AUTOSAR XML (schema 4-2-2)
package /ComponentTypes
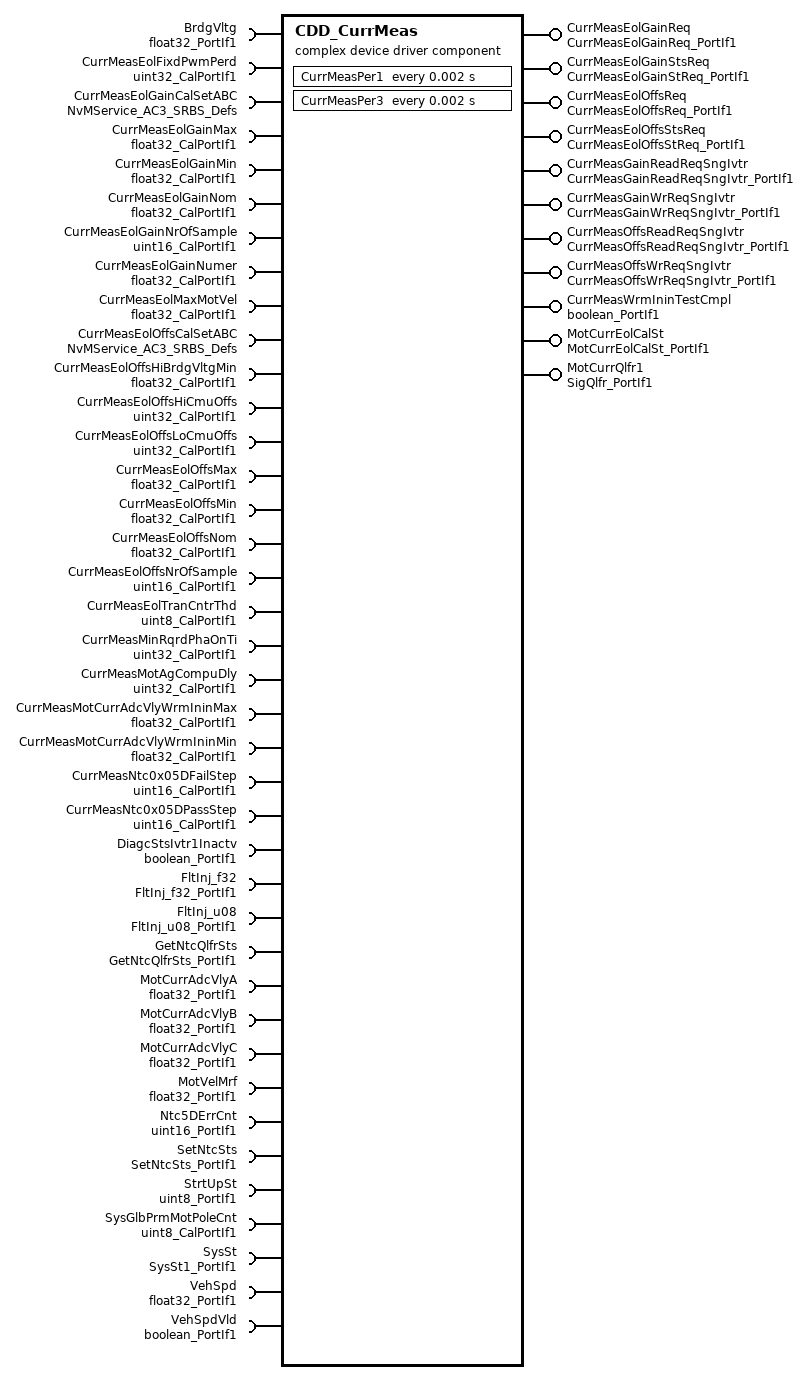
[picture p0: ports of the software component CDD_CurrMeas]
  complex device driver sw component type CDD_CurrMeas
    11 x provide port:
      CurrMeasEolGainReq: server-com-spec{operation=Oper, queue-length=1}, provided-interface=CurrMeasEolGainReq_PortIf1
      CurrMeasEolGainStsReq: server-com-spec{operation=Oper, queue-length=1}, provided-interface=CurrMeasEolGainStReq_PortIf1
      CurrMeasEolOffsReq: server-com-spec{operation=Oper, queue-length=1}, provided-interface=CurrMeasEolOffsReq_PortIf1
      CurrMeasEolOffsStsReq: server-com-spec{operation=Oper, queue-length=1}, provided-interface=CurrMeasEolOffsStReq_PortIf1
      CurrMeasGainReadReqSngIvtr: server-com-spec{operation=Oper, queue-length=1}, provided-interface=CurrMeasGainReadReqSngIvtr_PortIf1
      CurrMeasGainWrReqSngIvtr: server-com-spec{operation=Oper, queue-length=1}, provided-interface=CurrMeasGainWrReqSngIvtr_PortIf1
      CurrMeasOffsReadReqSngIvtr: server-com-spec{operation=Oper, queue-length=1}, provided-interface=CurrMeasOffsReadReqSngIvtr_PortIf1
      CurrMeasOffsWrReqSngIvtr: server-com-spec{operation=Oper, queue-length=1}, provided-interface=CurrMeasOffsWrReqSngIvtr_PortIf1
      CurrMeasWrmIninTestCmpl: nonqueued-sender-com-spec{data-element=Logl, init-value=0}, provided-interface=boolean_PortIf1
      MotCurrEolCalSt: nonqueued-sender-com-spec{data-element=Val, init-value=0}, provided-interface=MotCurrEolCalSt_PortIf1
      MotCurrQlfr1: nonqueued-sender-com-spec{data-element=Val, init-value=0}, provided-interface=SigQlfr_PortIf1
    39 x require port:
      BrdgVltg: nonqueued-receiver-com-spec{data-element=Val, filter=data-filter-type=ALWAYS, init-value=6}, required-interface=float32_PortIf1
      CurrMeasEolFixdPwmPerd: parameter-require-com-spec{init-value=62500, parameter=Val}, required-interface=uint32_CalPortIf1
      CurrMeasEolGainCalSetABC: required-com-specs=[EraseBlock, GetErrorStatus, InvalidateNvBlock, ReadBlock, RestoreBlockDefaults, SetRamBlockStatus, WriteBlock], required-interface=NvMService_AC3_SRBS_Defs
      CurrMeasEolGainMax: parameter-require-com-spec{init-value=76, parameter=Val}, required-interface=float32_CalPortIf1
      CurrMeasEolGainMin: parameter-require-com-spec{init-value=56, parameter=Val}, required-interface=float32_CalPortIf1
      CurrMeasEolGainNom: parameter-require-com-spec{init-value=66.66, parameter=Val}, required-interface=float32_CalPortIf1
      CurrMeasEolGainNrOfSample: parameter-require-com-spec{init-value=5, parameter=Val}, required-interface=uint16_CalPortIf1
      CurrMeasEolGainNumer: parameter-require-com-spec{init-value=45, parameter=Val}, required-interface=float32_CalPortIf1
      CurrMeasEolMaxMotVel: parameter-require-com-spec{init-value=16, parameter=Val}, required-interface=float32_CalPortIf1
      CurrMeasEolOffsCalSetABC: required-com-specs=[EraseBlock, GetErrorStatus, InvalidateNvBlock, ReadBlock, RestoreBlockDefaults, SetRamBlockStatus, WriteBlock], required-interface=NvMService_AC3_SRBS_Defs
      CurrMeasEolOffsHiBrdgVltgMin: parameter-require-com-spec{init-value=262500, parameter=Val}, required-interface=float32_CalPortIf1
      CurrMeasEolOffsHiCmuOffs: parameter-require-com-spec{init-value=50000, parameter=Val}, required-interface=uint32_CalPortIf1
      CurrMeasEolOffsLoCmuOffs: parameter-require-com-spec{init-value=6250, parameter=Val}, required-interface=uint32_CalPortIf1
      CurrMeasEolOffsMax: parameter-require-com-spec{init-value=2.8, parameter=Val}, required-interface=float32_CalPortIf1
      CurrMeasEolOffsMin: parameter-require-com-spec{init-value=2.3, parameter=Val}, required-interface=float32_CalPortIf1
      CurrMeasEolOffsNom: parameter-require-com-spec{init-value=2.5, parameter=Val}, required-interface=float32_CalPortIf1
      CurrMeasEolOffsNrOfSample: parameter-require-com-spec{init-value=20, parameter=Val}, required-interface=uint16_CalPortIf1
      CurrMeasEolTranCntrThd: parameter-require-com-spec{init-value=5, parameter=Val}, required-interface=uint8_CalPortIf1
      CurrMeasMinRqrdPhaOnTi: parameter-require-com-spec{init-value=11000, parameter=Val}, required-interface=uint32_CalPortIf1
      CurrMeasMotAgCompuDly: parameter-require-com-spec{init-value=30000, parameter=Val}, required-interface=uint32_CalPortIf1
      CurrMeasMotCurrAdcVlyWrmIninMax: parameter-require-com-spec{init-value=3, parameter=Val}, required-interface=float32_CalPortIf1
      CurrMeasMotCurrAdcVlyWrmIninMin: parameter-require-com-spec{init-value=2, parameter=Val}, required-interface=float32_CalPortIf1
      CurrMeasNtc0x05DFailStep: parameter-require-com-spec{init-value=16384, parameter=Val}, required-interface=uint16_CalPortIf1
      CurrMeasNtc0x05DPassStep: parameter-require-com-spec{init-value=16384, parameter=Val}, required-interface=uint16_CalPortIf1
      DiagcStsIvtr1Inactv: nonqueued-receiver-com-spec{data-element=Logl, filter=data-filter-type=ALWAYS, init-value=0}, required-interface=boolean_PortIf1
      FltInj_f32: client-com-spec=Oper, required-interface=FltInj_f32_PortIf1
      FltInj_u08: client-com-spec=Oper, required-interface=FltInj_u08_PortIf1
      GetNtcQlfrSts: client-com-spec=Oper, required-interface=GetNtcQlfrSts_PortIf1
      MotCurrAdcVlyA: nonqueued-receiver-com-spec{data-element=Val, filter=data-filter-type=ALWAYS, init-value=0}, required-interface=float32_PortIf1
      MotCurrAdcVlyB: nonqueued-receiver-com-spec{data-element=Val, filter=data-filter-type=ALWAYS, init-value=0}, required-interface=float32_PortIf1
      MotCurrAdcVlyC: nonqueued-receiver-com-spec{data-element=Val, filter=data-filter-type=ALWAYS, init-value=0}, required-interface=float32_PortIf1
      MotVelMrf: nonqueued-receiver-com-spec{data-element=Val, filter=data-filter-type=ALWAYS, init-value=0}, required-interface=float32_PortIf1
      Ntc5DErrCnt: nonqueued-receiver-com-spec{data-element=Val, filter=data-filter-type=ALWAYS, init-value=0}, required-interface=uint16_PortIf1
      SetNtcSts: client-com-spec=Oper, required-interface=SetNtcSts_PortIf1
      StrtUpSt: nonqueued-receiver-com-spec{data-element=Val, filter=data-filter-type=ALWAYS, init-value=0}, required-interface=uint8_PortIf1
      SysGlbPrmMotPoleCnt: parameter-require-com-spec{init-value=8, parameter=Val}, required-interface=uint8_CalPortIf1
      SysSt: nonqueued-receiver-com-spec{data-element=Val, filter=data-filter-type=ALWAYS, init-value=3}, required-interface=SysSt1_PortIf1
      VehSpd: nonqueued-receiver-com-spec{data-element=Val, filter=data-filter-type=ALWAYS, init-value=0}, required-interface=float32_PortIf1
      VehSpdVld: nonqueued-receiver-com-spec{data-element=Logl, filter=data-filter-type=ALWAYS, init-value=0}, required-interface=boolean_PortIf1
    behavior CDD_CurrMeas_InternalBehavior
      ar-typed-per-instance-memorys:
        36 x data, all with sw-calibration-access=READ-ONLY:
          BrdgVltgSumPrev: type=float32
          CurrMeasEolGainCalSetABC: type=CurrMeasEolGainCal3PhaRec1
          CurrMeasEolOffsCalSetABC: type=CurrMeasEolOffsCal3PhaRec1
          EolGainSts: type=uint8
          EolGainTranCntrPrev: type=uint8
          EolOffsHiBrdgVltg: type=float32
          EolOffsSts: type=uint8
          EolOffsTranCntrPrev: type=uint8
          GainEolAvrgCntrPrev: type=uint16
          MotCtrlNtc5DErrCntPrev: type=uint16
          MotCurrEolCalStPrev: type=MotCurrEolCalSt2
          MotCurrEolGainA: type=float32
          MotCurrEolGainB: type=float32
          MotCurrEolGainC: type=float32
          MotCurrEolOffsProcFlg: type=boolean
          MotCurrOffsDeltaA: type=float32
          MotCurrOffsDeltaB: type=float32
          MotCurrOffsDeltaC: type=float32
          MotCurrOffsHiAvrgA: type=float32
          MotCurrOffsHiAvrgB: type=float32
          MotCurrOffsHiAvrgC: type=float32
          MotCurrOffsLoAvrgA: type=float32
          MotCurrOffsLoAvrgB: type=float32
          MotCurrOffsLoAvrgC: type=float32
          MotCurrOffsZeroAvrgA: type=float32
          MotCurrOffsZeroAvrgB: type=float32
          MotCurrOffsZeroAvrgC: type=float32
          MotCurrRollgCnt1Prev: type=uint8
          MotCurrSumAPrev: type=float32
          MotCurrSumBPrev: type=float32
          MotCurrSumCPrev: type=float32
          Ntc5DErrCnt2MilliSecPrev: type=uint16
          OffsEolAvrgCntrPrev: type=uint16
          PhaOnTiErrCntPrev: type=uint16
          TmpMotCurrAdcVlySum1Prev: type=float32
          WrmIninTestCmplPrev: type=boolean
      6 x operation invoked event:
        OIT_CurrMeasEolGainReq_Oper_CurrMeasEolGainReq_Oper: start-on-event=CurrMeasEolGainReq_Oper, operation=CurrMeasEolGainReq.Oper
        OIT_CurrMeasEolGainStsReq_Oper_CurrMeasEolGainStsReq_Oper: start-on-event=CurrMeasEolGainStsReq_Oper, operation=CurrMeasEolGainStsReq.Oper
        OIT_CurrMeasEolOffsReq_Oper_CurrMeasEolOffsReq_Oper: start-on-event=CurrMeasEolOffsReq_Oper, operation=CurrMeasEolOffsReq.Oper
        OIT_CurrMeasEolOffsStsReq_Oper_CurrMeasEolOffsStsReq_Oper: start-on-event=CurrMeasEolOffsStsReq_Oper, operation=CurrMeasEolOffsStsReq.Oper
        OIT_CurrMeasGainReadReqSngIvtr_Oper_CurrMeasGainReadReqSngIvtr_Oper: start-on-event=CurrMeasGainReadReqSngIvtr_Oper, operation=CurrMeasGainReadReqSngIvtr.Oper
        OIT_CurrMeasGainWrReqSngIvtr_Oper_CurrMeasGainWrReqSngIvtr_Oper: start-on-event=CurrMeasGainWrReqSngIvtr_Oper, operation=CurrMeasGainWrReqSngIvtr.Oper
      init event CDD_CurrMeas_InitEvent: start-on-event=CurrMeasInit1
      operation invoked event OIT_CurrMeasOffsReadReqSngIvtr_Oper_CurrMeasOffsReadReqSngIvtr_Oper: start-on-event=CurrMeasOffsReadReqSngIvtr_Oper, operation=CurrMeasOffsReadReqSngIvtr.Oper
      operation invoked event OIT_CurrMeasOffsWrReqSngIvtr_Oper_CurrMeasOffsWrReqSngIvtr_Oper: start-on-event=CurrMeasOffsWrReqSngIvtr_Oper, operation=CurrMeasOffsWrReqSngIvtr.Oper
      timing event TMT_CurrMeasPer1: start-on-event=CurrMeasPer1, period=0.002
      timing event TMT_CurrMeasPer3: start-on-event=CurrMeasPer3, period=0.002
      port-api-options:
        enable-take-address=false, error-handling=NO-TRANSFORMER-ERROR-HANDLING, indirect-api=false, port=CurrMeasEolFixdPwmPerd
        enable-take-address=false, error-handling=NO-TRANSFORMER-ERROR-HANDLING, indirect-api=false, port=CurrMeasEolGainCalSetABC
        enable-take-address=false, error-handling=NO-TRANSFORMER-ERROR-HANDLING, indirect-api=false, port=CurrMeasEolGainMax
        enable-take-address=false, error-handling=NO-TRANSFORMER-ERROR-HANDLING, indirect-api=false, port=CurrMeasEolGainMin
        enable-take-address=false, error-handling=NO-TRANSFORMER-ERROR-HANDLING, indirect-api=false, port=CurrMeasEolGainNom
        enable-take-address=false, error-handling=NO-TRANSFORMER-ERROR-HANDLING, indirect-api=false, port=CurrMeasEolGainNrOfSample
        enable-take-address=false, error-handling=NO-TRANSFORMER-ERROR-HANDLING, indirect-api=false, port=CurrMeasEolGainNumer
        enable-take-address=false, error-handling=NO-TRANSFORMER-ERROR-HANDLING, indirect-api=false, port=CurrMeasEolGainReq
        enable-take-address=false, error-handling=NO-TRANSFORMER-ERROR-HANDLING, indirect-api=false, port=CurrMeasEolGainStsReq
        enable-take-address=false, error-handling=NO-TRANSFORMER-ERROR-HANDLING, indirect-api=false, port=CurrMeasEolMaxMotVel
        enable-take-address=false, error-handling=NO-TRANSFORMER-ERROR-HANDLING, indirect-api=false, port=CurrMeasEolOffsCalSetABC
        enable-take-address=false, error-handling=NO-TRANSFORMER-ERROR-HANDLING, indirect-api=false, port=CurrMeasEolOffsHiBrdgVltgMin
        enable-take-address=false, error-handling=NO-TRANSFORMER-ERROR-HANDLING, indirect-api=false, port=CurrMeasEolOffsHiCmuOffs
        enable-take-address=false, error-handling=NO-TRANSFORMER-ERROR-HANDLING, indirect-api=false, port=CurrMeasEolOffsLoCmuOffs
        enable-take-address=false, error-handling=NO-TRANSFORMER-ERROR-HANDLING, indirect-api=false, port=CurrMeasEolOffsMax
        enable-take-address=false, error-handling=NO-TRANSFORMER-ERROR-HANDLING, indirect-api=false, port=CurrMeasEolOffsMin
        enable-take-address=false, error-handling=NO-TRANSFORMER-ERROR-HANDLING, indirect-api=false, port=CurrMeasEolOffsNom
        enable-take-address=false, error-handling=NO-TRANSFORMER-ERROR-HANDLING, indirect-api=false, port=CurrMeasEolOffsNrOfSample
        enable-take-address=false, error-handling=NO-TRANSFORMER-ERROR-HANDLING, indirect-api=false, port=CurrMeasEolOffsReq
        enable-take-address=false, error-handling=NO-TRANSFORMER-ERROR-HANDLING, indirect-api=false, port=CurrMeasEolOffsStsReq
        enable-take-address=false, error-handling=NO-TRANSFORMER-ERROR-HANDLING, indirect-api=false, port=CurrMeasEolTranCntrThd
        enable-take-address=false, error-handling=NO-TRANSFORMER-ERROR-HANDLING, indirect-api=false, port=CurrMeasGainReadReqSngIvtr
        enable-take-address=false, error-handling=NO-TRANSFORMER-ERROR-HANDLING, indirect-api=false, port=CurrMeasGainWrReqSngIvtr
        enable-take-address=false, error-handling=NO-TRANSFORMER-ERROR-HANDLING, indirect-api=false, port=CurrMeasMinRqrdPhaOnTi
        enable-take-address=false, error-handling=NO-TRANSFORMER-ERROR-HANDLING, indirect-api=false, port=CurrMeasMotAgCompuDly
        enable-take-address=false, error-handling=NO-TRANSFORMER-ERROR-HANDLING, indirect-api=false, port=CurrMeasMotCurrAdcVlyWrmIninMax
        enable-take-address=false, error-handling=NO-TRANSFORMER-ERROR-HANDLING, indirect-api=false, port=CurrMeasMotCurrAdcVlyWrmIninMin
        enable-take-address=false, error-handling=NO-TRANSFORMER-ERROR-HANDLING, indirect-api=false, port=CurrMeasNtc0x05DFailStep
        enable-take-address=false, error-handling=NO-TRANSFORMER-ERROR-HANDLING, indirect-api=false, port=CurrMeasNtc0x05DPassStep
        enable-take-address=false, error-handling=NO-TRANSFORMER-ERROR-HANDLING, indirect-api=false, port=CurrMeasOffsReadReqSngIvtr
        enable-take-address=false, error-handling=NO-TRANSFORMER-ERROR-HANDLING, indirect-api=false, port=CurrMeasOffsWrReqSngIvtr
        enable-take-address=false, error-handling=NO-TRANSFORMER-ERROR-HANDLING, indirect-api=false, port=CurrMeasWrmIninTestCmpl
        enable-take-address=false, error-handling=NO-TRANSFORMER-ERROR-HANDLING, indirect-api=false, port=DiagcStsIvtr1Inactv
        enable-take-address=false, error-handling=NO-TRANSFORMER-ERROR-HANDLING, indirect-api=false, port=FltInj_f32
        enable-take-address=false, error-handling=NO-TRANSFORMER-ERROR-HANDLING, indirect-api=false, port=FltInj_u08
        enable-take-address=false, error-handling=NO-TRANSFORMER-ERROR-HANDLING, indirect-api=false, port=GetNtcQlfrSts
        enable-take-address=false, error-handling=NO-TRANSFORMER-ERROR-HANDLING, indirect-api=false, port=MotCurrAdcVlyA
        enable-take-address=false, error-handling=NO-TRANSFORMER-ERROR-HANDLING, indirect-api=false, port=MotCurrAdcVlyB
        enable-take-address=false, error-handling=NO-TRANSFORMER-ERROR-HANDLING, indirect-api=false, port=MotCurrAdcVlyC
        enable-take-address=false, error-handling=NO-TRANSFORMER-ERROR-HANDLING, indirect-api=false, port=MotCurrEolCalSt
        enable-take-address=false, error-handling=NO-TRANSFORMER-ERROR-HANDLING, indirect-api=false, port=MotCurrQlfr1
        enable-take-address=false, error-handling=NO-TRANSFORMER-ERROR-HANDLING, indirect-api=false, port=MotVelMrf
        enable-take-address=false, error-handling=NO-TRANSFORMER-ERROR-HANDLING, indirect-api=false, port=Ntc5DErrCnt
        enable-take-address=false, error-handling=NO-TRANSFORMER-ERROR-HANDLING, indirect-api=false, port=SetNtcSts
        enable-take-address=false, error-handling=NO-TRANSFORMER-ERROR-HANDLING, indirect-api=false, port=StrtUpSt
        enable-take-address=false, error-handling=NO-TRANSFORMER-ERROR-HANDLING, indirect-api=false, port=SysGlbPrmMotPoleCnt
        enable-take-address=false, error-handling=NO-TRANSFORMER-ERROR-HANDLING, indirect-api=false, port=SysSt
        enable-take-address=false, error-handling=NO-TRANSFORMER-ERROR-HANDLING, indirect-api=false, port=VehSpd
        enable-take-address=false, error-handling=NO-TRANSFORMER-ERROR-HANDLING, indirect-api=false, port=VehSpdVld
      11 x runnable:
        CurrMeasEolGainReq_Oper
        CurrMeasEolGainStsReq_Oper
        CurrMeasEolOffsReq_Oper
        CurrMeasEolOffsStsReq_Oper
        CurrMeasGainReadReqSngIvtr_Oper
        CurrMeasGainWrReqSngIvtr_Oper
          sync call SC_CurrMeasEolGainCalSetABC_SetRamBlockStatus: operation=CurrMeasEolGainCalSetABC.SetRamBlockStatus, timeout=0
        CurrMeasInit1
          sync call SC_CurrMeasEolGainCalSetABC_GetErrorStatus: operation=CurrMeasEolGainCalSetABC.GetErrorStatus, timeout=0
          sync call SC_CurrMeasEolOffsCalSetABC_GetErrorStatus: operation=CurrMeasEolOffsCalSetABC.GetErrorStatus, timeout=0
          sync call SC_SetNtcSts_Oper: operation=SetNtcSts.Oper, timeout=0
        CurrMeasOffsReadReqSngIvtr_Oper
        CurrMeasOffsWrReqSngIvtr_Oper
          sync call SC_CurrMeasEolGainCalSetABC_SetRamBlockStatus: operation=CurrMeasEolGainCalSetABC.SetRamBlockStatus, timeout=0
          sync call SC_CurrMeasEolOffsCalSetABC_SetRamBlockStatus: operation=CurrMeasEolOffsCalSetABC.SetRamBlockStatus, timeout=0
        CurrMeasPer1
          data-receive-point-by-arguments:
            8 x access:
              REC_BrdgVltg_Val: accessed-variable=BrdgVltg.Val
              REC_DiagcStsIvtr1Inactv_Logl: accessed-variable=DiagcStsIvtr1Inactv.Logl
              REC_MotCurrAdcVlyA_Val: accessed-variable=MotCurrAdcVlyA.Val
              REC_MotCurrAdcVlyB_Val: accessed-variable=MotCurrAdcVlyB.Val
              REC_MotCurrAdcVlyC_Val: accessed-variable=MotCurrAdcVlyC.Val
              REC_MotVelMrf_Val: accessed-variable=MotVelMrf.Val
              REC_VehSpd_Val: accessed-variable=VehSpd.Val
              REC_VehSpdVld_Logl: accessed-variable=VehSpdVld.Logl
          data-send-points:
            access SEND_MotCurrEolCalSt_Val: accessed-variable=MotCurrEolCalSt.Val
          sync call SC_CurrMeasEolGainCalSetABC_SetRamBlockStatus: operation=CurrMeasEolGainCalSetABC.SetRamBlockStatus, timeout=0
          sync call SC_CurrMeasEolOffsCalSetABC_SetRamBlockStatus: operation=CurrMeasEolOffsCalSetABC.SetRamBlockStatus, timeout=0
          sync call SC_SetNtcSts_Oper: operation=SetNtcSts.Oper, timeout=0
        CurrMeasPer3
          data-receive-point-by-arguments:
            7 x access:
              REC_DiagcStsIvtr1Inactv_Logl: accessed-variable=DiagcStsIvtr1Inactv.Logl
              REC_MotCurrAdcVlyA_Val: accessed-variable=MotCurrAdcVlyA.Val
              REC_MotCurrAdcVlyB_Val: accessed-variable=MotCurrAdcVlyB.Val
              REC_MotCurrAdcVlyC_Val: accessed-variable=MotCurrAdcVlyC.Val
              REC_Ntc5DErrCnt_Val: accessed-variable=Ntc5DErrCnt.Val
              REC_StrtUpSt_Val: accessed-variable=StrtUpSt.Val
              REC_SysSt_Val: accessed-variable=SysSt.Val
          data-send-points:
            access SEND_CurrMeasWrmIninTestCmpl_Logl: accessed-variable=CurrMeasWrmIninTestCmpl.Logl
            access SEND_MotCurrQlfr1_Val: accessed-variable=MotCurrQlfr1.Val
          sync call SC_GetNtcQlfrSts_Oper: operation=GetNtcQlfrSts.Oper, timeout=0
          sync call SC_SetNtcSts_Oper: operation=SetNtcSts.Oper, timeout=0
      swc service dependency NvmCurrMeasEolGainCalSetABC: assigned-ports=role-based-port-assignment={port-prototype=CurrMeasEolGainCalSetABC, role=NvMService_AC3_SRBS_Defs}
        assigned-datas:
          role=ramBlock, used-data-element=CurrMeasEolGainCalSetABC
          role=defaultValue, used-parameter-element=CurrMeasEolGainCalSetABCDft
        service-needs:
          nv block needs NvmCurrMeasEolGainCalSetABC: n-data-sets=0, ram-block-status-control=API, readonly=false, reliability=ERROR-DETECTION, resistant-to-changed-sw=true, restore-at-start=true, store-at-shutdown=true, write-only-once=false, writing-frequency=0, writing-priority=LOW
      swc service dependency NvmCurrMeasEolOffsCalSetABC: assigned-ports=role-based-port-assignment={port-prototype=CurrMeasEolOffsCalSetABC, role=NvMService_AC3_SRBS_Defs}
        assigned-datas:
          role=ramBlock, used-data-element=CurrMeasEolOffsCalSetABC
          role=defaultValue, used-parameter-element=CurrMeasEolOffsCalSetABCDft
        service-needs:
          nv block needs NvmCurrMeasEolOffsCalSetABC: n-data-sets=0, ram-block-status-control=API, readonly=false, reliability=ERROR-DETECTION, resistant-to-changed-sw=true, restore-at-start=true, store-at-shutdown=true, write-only-once=false, writing-frequency=0, writing-priority=LOW
      shared-parameters:
        parameter data prototype CurrMeasEolGainCalSetABCDft: sw-calibration-access=READ-WRITE, type=CurrMeasEolGainCal3PhaRec1, init-value=fields=[CurrMeasMotCurrEolGainA:66.66, CurrMeasMotCurrEolGainB:66.66, CurrMeasMotCurrEolGainC:66.66]
        parameter data prototype CurrMeasEolOffsCalSetABCDft: sw-calibration-access=READ-WRITE, type=CurrMeasEolOffsCal3PhaRec1, init-value=fields=[CurrMeasEolOffsHiBrdgVltg:700000, CurrMeasMotCurrEolOffsDifA:0, CurrMeasMotCurrEolOffsDifB:0, CurrMeasMotCurrEolOffsDifC:0, CurrMeasMotCurrOffsLoAvrgA:2.5, CurrMeasMotCurrOffsLoAvrgB:2.5, CurrMeasMotCurrOffsLoAvrgC:2.5]
  swc implementation CDD_CurrMeas_Implementation: behavior=CDD_CurrMeas_InternalBehavior
    code-descriptors:
      code Default: artifact-descriptors=autosar-engineering-object={short-label=Default, category=SWSRC}
